VERSION ""

NS_ :

BS_:

BU_: UNIT_BMS MASTER_BMS
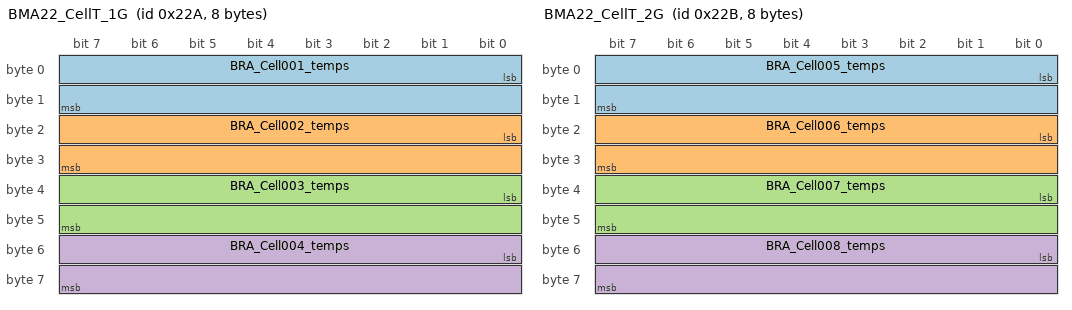
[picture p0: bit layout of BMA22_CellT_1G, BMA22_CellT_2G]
BO_ 554 BMA22_CellT_1G: 8 UNIT_BMS MASTER_BMS
 SG_ BRA_Cell001_temps : 0|16@1- (0.1,0) [-40.0|100.0] "℃"  UNIT_BMS MASTER_BMS
 SG_ BRA_Cell002_temps : 16|16@1- (0.1,0) [-40.0|100.0] "℃"  UNIT_BMS MASTER_BMS
 SG_ BRA_Cell003_temps : 32|16@1- (0.1,0) [-40.0|100.0] "℃"  UNIT_BMS MASTER_BMS
 SG_ BRA_Cell004_temps : 48|16@1- (0.1,0) [-40.0|100.0] "℃"  UNIT_BMS MASTER_BMS
BO_ 555 BMA22_CellT_2G: 8 UNIT_BMS MASTER_BMS
 SG_ BRA_Cell005_temps : 0|16@1- (0.1,0) [-40.0|100.0] "℃"  UNIT_BMS MASTER_BMS
 SG_ BRA_Cell006_temps : 16|16@1- (0.1,0) [-40.0|100.0] "℃"  UNIT_BMS MASTER_BMS
 SG_ BRA_Cell007_temps : 32|16@1- (0.1,0) [-40.0|100.0] "℃"  UNIT_BMS MASTER_BMS
 SG_ BRA_Cell008_temps : 48|16@1- (0.1,0) [-40.0|100.0] "℃"  UNIT_BMS MASTER_BMS
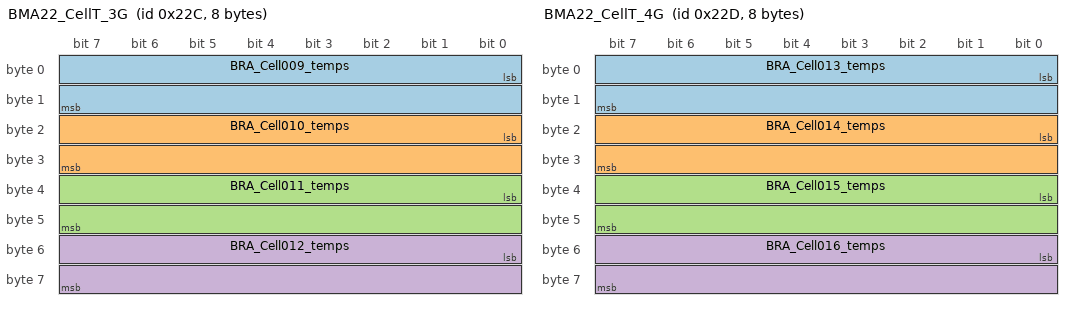
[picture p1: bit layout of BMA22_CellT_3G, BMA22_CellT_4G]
BO_ 556 BMA22_CellT_3G: 8 UNIT_BMS MASTER_BMS
 SG_ BRA_Cell009_temps : 0|16@1- (0.1,0) [-40.0|100.0] "℃"  UNIT_BMS MASTER_BMS
 SG_ BRA_Cell010_temps : 16|16@1- (0.1,0) [-40.0|100.0] "℃"  UNIT_BMS MASTER_BMS
 SG_ BRA_Cell011_temps : 32|16@1- (0.1,0) [-40.0|100.0] "℃"  UNIT_BMS MASTER_BMS
 SG_ BRA_Cell012_temps : 48|16@1- (0.1,0) [-40.0|100.0] "℃"  UNIT_BMS MASTER_BMS
BO_ 557 BMA22_CellT_4G: 8 UNIT_BMS MASTER_BMS
 SG_ BRA_Cell013_temps : 0|16@1- (0.1,0) [-40.0|100.0] "℃"  UNIT_BMS MASTER_BMS
 SG_ BRA_Cell014_temps : 16|16@1- (0.1,0) [-40.0|100.0] "℃"  UNIT_BMS MASTER_BMS
 SG_ BRA_Cell015_temps : 32|16@1- (0.1,0) [-40.0|100.0] "℃"  UNIT_BMS MASTER_BMS
 SG_ BRA_Cell016_temps : 48|16@1- (0.1,0) [-40.0|100.0] "℃"  UNIT_BMS MASTER_BMS
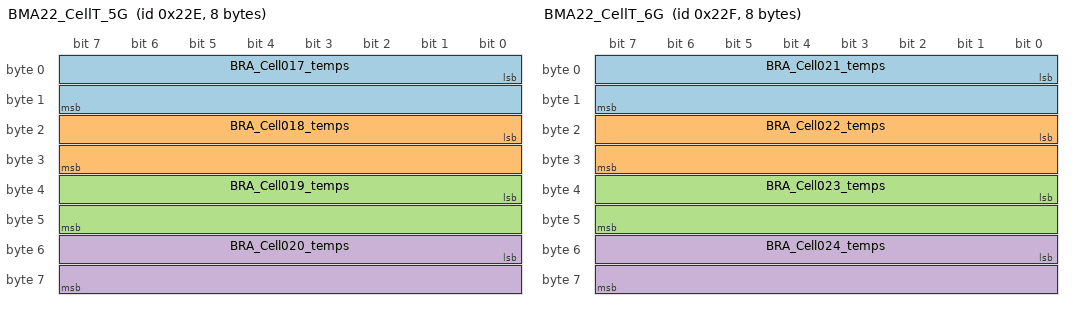
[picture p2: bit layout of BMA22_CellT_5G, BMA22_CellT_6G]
BO_ 558 BMA22_CellT_5G: 8 UNIT_BMS MASTER_BMS
 SG_ BRA_Cell017_temps : 0|16@1- (0.1,0) [-40.0|100.0] "℃"  UNIT_BMS MASTER_BMS
 SG_ BRA_Cell018_temps : 16|16@1- (0.1,0) [-40.0|100.0] "℃"  UNIT_BMS MASTER_BMS
 SG_ BRA_Cell019_temps : 32|16@1- (0.1,0) [-40.0|100.0] "℃"  UNIT_BMS MASTER_BMS
 SG_ BRA_Cell020_temps : 48|16@1- (0.1,0) [-40.0|100.0] "℃"  UNIT_BMS MASTER_BMS
BO_ 559 BMA22_CellT_6G: 8 UNIT_BMS MASTER_BMS
 SG_ BRA_Cell021_temps : 0|16@1- (0.1,0) [-40.0|100.0] "℃"  UNIT_BMS MASTER_BMS
 SG_ BRA_Cell022_temps : 16|16@1- (0.1,0) [-40.0|100.0] "℃"  UNIT_BMS MASTER_BMS
 SG_ BRA_Cell023_temps : 32|16@1- (0.1,0) [-40.0|100.0] "℃"  UNIT_BMS MASTER_BMS
 SG_ BRA_Cell024_temps : 48|16@1- (0.1,0) [-40.0|100.0] "℃"  UNIT_BMS MASTER_BMS
BO_ 546 BMA22_CellTempSate: 8 UNIT_BMS MASTER_BMS
 SG_ BMA_N_Cell_MaxT : 0|16@1- (0.1,0) [-40.0|100.0] "℃"  UNIT_BMS MASTER_BMS
 SG_ BMA_N_Cell_MinT : 8|16@1- (0.1,0) [-40.0|100.0] "℃"  UNIT_BMS MASTER_BMS
 SG_ BMA_N_Cell_AVGT : 16|16@1- (0.1,0) [-40.0|100.0] "℃"  UNIT_BMS MASTER_BMS
 SG_ BMA_N_Cell_DeviT : 48|16@1+ (0.1,0) [0.0|25.0] "℃"  UNIT_BMS MASTER_BMS
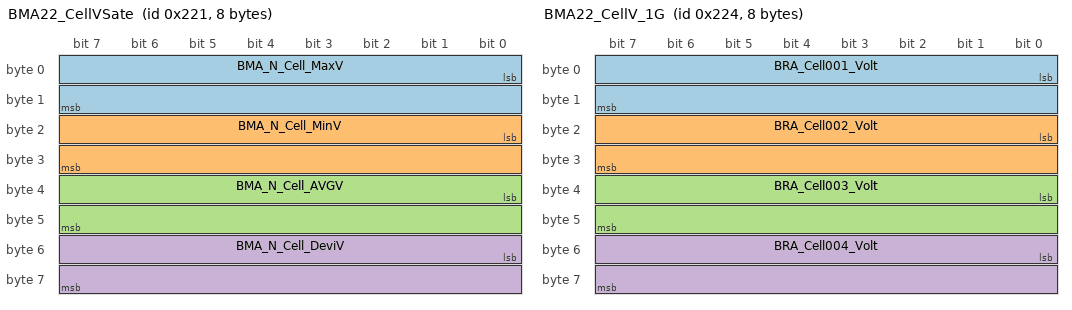
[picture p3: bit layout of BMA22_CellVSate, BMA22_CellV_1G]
BO_ 545 BMA22_CellVSate: 8 UNIT_BMS MASTER_BMS
 SG_ BMA_N_Cell_MaxV : 0|16@1+ (0.001,0) [2.8|4.5] "V"  UNIT_BMS MASTER_BMS
 SG_ BMA_N_Cell_MinV : 16|16@1+ (0.001,0) [2.8|4.5] "V"  UNIT_BMS MASTER_BMS
 SG_ BMA_N_Cell_AVGV : 32|16@1+ (0.001,0) [2.8|4.5] "V"  UNIT_BMS MASTER_BMS
 SG_ BMA_N_Cell_DeviV : 48|16@1+ (0.001,0) [0.0|5000.0] "mV"  UNIT_BMS MASTER_BMS
BO_ 548 BMA22_CellV_1G: 8 UNIT_BMS MASTER_BMS
 SG_ BRA_Cell001_Volt : 0|16@1+ (0.001,0) [2.8|4.5] "V"  UNIT_BMS MASTER_BMS
 SG_ BRA_Cell002_Volt : 16|16@1+ (0.001,0) [2.8|4.5] "V"  UNIT_BMS MASTER_BMS
 SG_ BRA_Cell003_Volt : 32|16@1+ (0.001,0) [2.8|4.5] "V"  UNIT_BMS MASTER_BMS
 SG_ BRA_Cell004_Volt : 48|16@1+ (0.001,0) [2.8|4.5] "V"  UNIT_BMS MASTER_BMS
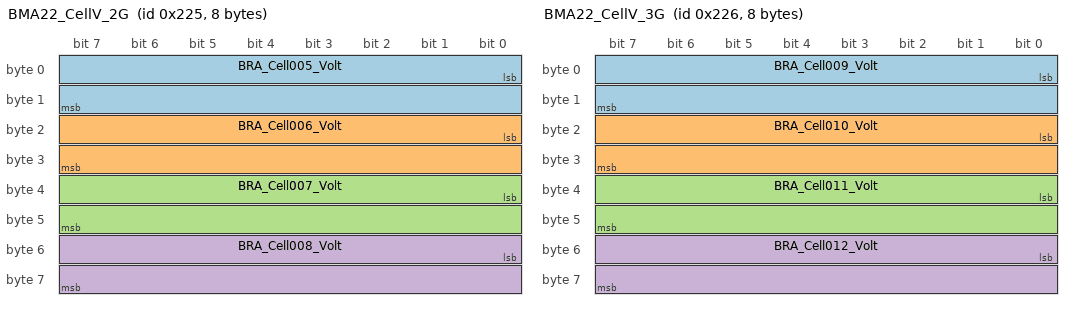
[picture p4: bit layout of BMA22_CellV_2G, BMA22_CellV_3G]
BO_ 549 BMA22_CellV_2G: 8 UNIT_BMS MASTER_BMS
 SG_ BRA_Cell005_Volt : 0|16@1+ (0.001,0) [2.8|4.5] "V"  UNIT_BMS MASTER_BMS
 SG_ BRA_Cell006_Volt : 16|16@1+ (0.001,0) [2.8|4.5] "V"  UNIT_BMS MASTER_BMS
 SG_ BRA_Cell007_Volt : 32|16@1+ (0.001,0) [2.8|4.5] "V"  UNIT_BMS MASTER_BMS
 SG_ BRA_Cell008_Volt : 48|16@1+ (0.001,0) [2.8|4.5] "V"  UNIT_BMS MASTER_BMS
BO_ 550 BMA22_CellV_3G: 8 UNIT_BMS MASTER_BMS
 SG_ BRA_Cell009_Volt : 0|16@1+ (0.001,0) [2.8|4.5] "V"  UNIT_BMS MASTER_BMS
 SG_ BRA_Cell010_Volt : 16|16@1+ (0.001,0) [2.8|4.5] "V"  UNIT_BMS MASTER_BMS
 SG_ BRA_Cell011_Volt : 32|16@1+ (0.001,0) [2.8|4.5] "V"  UNIT_BMS MASTER_BMS
 SG_ BRA_Cell012_Volt : 48|16@1+ (0.001,0) [2.8|4.5] "V"  UNIT_BMS MASTER_BMS
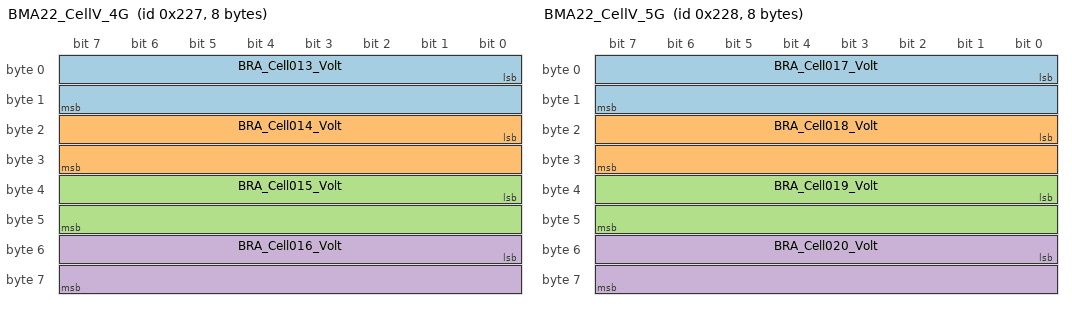
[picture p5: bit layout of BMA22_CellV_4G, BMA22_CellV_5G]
BO_ 551 BMA22_CellV_4G: 8 UNIT_BMS MASTER_BMS
 SG_ BRA_Cell013_Volt : 0|16@1+ (0.001,0) [2.8|4.5] "V"  UNIT_BMS MASTER_BMS
 SG_ BRA_Cell014_Volt : 16|16@1+ (0.001,0) [2.8|4.5] "V"  UNIT_BMS MASTER_BMS
 SG_ BRA_Cell015_Volt : 32|16@1+ (0.001,0) [2.8|4.5] "V"  UNIT_BMS MASTER_BMS
 SG_ BRA_Cell016_Volt : 48|16@1+ (0.001,0) [2.8|4.5] "V"  UNIT_BMS MASTER_BMS
BO_ 552 BMA22_CellV_5G: 8 UNIT_BMS MASTER_BMS
 SG_ BRA_Cell017_Volt : 0|16@1+ (0.001,0) [2.8|4.5] "V"  UNIT_BMS MASTER_BMS
 SG_ BRA_Cell018_Volt : 16|16@1+ (0.001,0) [2.8|4.5] "V"  UNIT_BMS MASTER_BMS
 SG_ BRA_Cell019_Volt : 32|16@1+ (0.001,0) [2.8|4.5] "V"  UNIT_BMS MASTER_BMS
 SG_ BRA_Cell020_Volt : 48|16@1+ (0.001,0) [2.8|4.5] "V"  UNIT_BMS MASTER_BMS
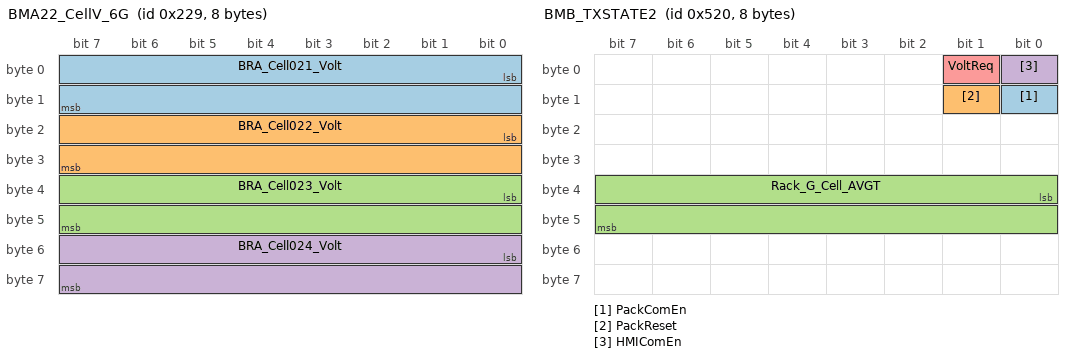
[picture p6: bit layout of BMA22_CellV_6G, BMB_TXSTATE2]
BO_ 553 BMA22_CellV_6G: 8 UNIT_BMS MASTER_BMS
 SG_ BRA_Cell021_Volt : 0|16@1+ (0.001,0) [2.8|4.5] "V"  UNIT_BMS MASTER_BMS
 SG_ BRA_Cell022_Volt : 16|16@1+ (0.001,0) [2.8|4.5] "V"  UNIT_BMS MASTER_BMS
 SG_ BRA_Cell023_Volt : 32|16@1+ (0.001,0) [2.8|4.5] "V"  UNIT_BMS MASTER_BMS
 SG_ BRA_Cell024_Volt : 48|16@1+ (0.001,0) [2.8|4.5] "V"  UNIT_BMS MASTER_BMS
BO_ 544 BMA22_Infro: 8 UNIT_BMS MASTER_BMS
 SG_ Rack_G_Cell_MinV : 48|16@1+ (0.001,0) [2.8|4.5] "V"  UNIT_BMS MASTER_BMS
 SG_ HMI_G_Cell_MinV : 48|16@1+ (0.001,0) [2.8|4.5] "V"  UNIT_BMS MASTER_BMS
 SG_ BMA_N_Nor_Voltage : 16|8@1+ (0.1,0) [30.0|100.0] "V"  UNIT_BMS MASTER_BMS
 SG_ BMA_N_Capacity : 32|16@1+ (1.0,0) [0.0|200.0] "Ah"  UNIT_BMS MASTER_BMS
 SG_ BMA_N_SYS_BMS_MinVoltage : 48|16@1+ (0.1,0) [30.0|60.0] "V"  UNIT_BMS MASTER_BMS
BO_ 547 BMA22_VoltProtect: 8 UNIT_BMS MASTER_BMS
 SG_ BMA_N_TotalVolte : 0|16@1+ (0.1,0) [30.0|100.0] "V"  UNIT_BMS MASTER_BMS
 SG_ BMA_N_CellMaxVoltNum : 8|8@1+ (1.0,0) [0.0|24.0] "C"  UNIT_BMS MASTER_BMS
 SG_ BMA_N_CellMinVoltNum : 16|8@1+ (1.0,0) [0.0|24.0] "C"  UNIT_BMS MASTER_BMS
 SG_ BMA_N_CellMaxTempsNum : 24|8@1+ (1.0,0) [0.0|24.0] "C"  UNIT_BMS MASTER_BMS
 SG_ BMA_N_CellMaxTempsNum : 32|8@1+ (1.0,0) [0.0|24.0] "C"  UNIT_BMS MASTER_BMS
 SG_ BMA_N__INITOK : 33|1@1- (1.0,0) [0.0|1.0] "F"  UNIT_BMS MASTER_BMS
 SG_ BMA_N__Fault : 34|1@1- (1.0,0) [0.0|1.0] "F"  UNIT_BMS MASTER_BMS
 SG_ BMA_N__Balan_On_OFF : 35|1@1- (1.0,0) [0.0|1.0] "F"  UNIT_BMS MASTER_BMS
 SG_ BMA_N_Waterleak_Err : 36|1@1- (1.0,0) [0.0|1.0] "F"  UNIT_BMS MASTER_BMS
 SG_ BMA_N_CellVolt_Err : 37|1@1- (1.0,0) [0.0|1.0] "F"  UNIT_BMS MASTER_BMS
 SG_ BMA_N_CellTemps_Err : 38|1@1- (1.0,0) [0.0|1.0] "F"  UNIT_BMS MASTER_BMS
 SG_ BMA_N_BATIC_Err : 39|1@1- (1.0,0) [0.0|1.0] "F"  UNIT_BMS MASTER_BMS
 SG_ BMA_N_CTCOM_Err : 40|1@1- (1.0,0) [0.0|1.0] "F"  UNIT_BMS MASTER_BMS
BO_ 1312 BMB_TXSTATE2: 8 UNIT_BMS MASTER_BMS
 SG_ PackComEn : 8|1@1- (1.0,0) [0.0|1.0] "F"  UNIT_BMS MASTER_BMS
 SG_ PackReset : 9|1@1- (1.0,0) [0.0|1.0] "F"  UNIT_BMS MASTER_BMS
 SG_ Rack_G_Cell_AVGT : 32|16@1- (0.1,0) [-40.0|100.0] "℃"  UNIT_BMS MASTER_BMS
 SG_ HMIComEn : 0|1@1- (1.0,0) [0.0|1.0] "F"  UNIT_BMS MASTER_BMS
 SG_ VoltReq : 1|1@1- (1.0,0) [0.0|1.0] "F"  UNIT_BMS MASTER_BMS
BO_ 1314 HMI_STATE2: 8 UNIT_BMS MASTER_BMS
 SG_ TempsReq : 2|1@1- (1.0,0) [0.0|1.0] "F"  UNIT_BMS MASTER_BMS
 SG_ HMI_G_Cell_AVGT : 32|16@1- (0.1,0) [-40.0|100.0] "℃"  UNIT_BMS MASTER_BMS
 SG_ PackStatus : 0|1@1- (1.0,0) [0.0|1.0] "F"  UNIT_BMS MASTER_BMS
 SG_ BMA_N_Volt_Qty : 0|8@1+ (1.0,0) [0.0|24.0] "EA"  UNIT_BMS MASTER_BMS
 SG_ BMA_N_SW_Ver : 8|8@1+ (1.0,0) [1.0|256.0] "REV"  UNIT_BMS MASTER_BMS
